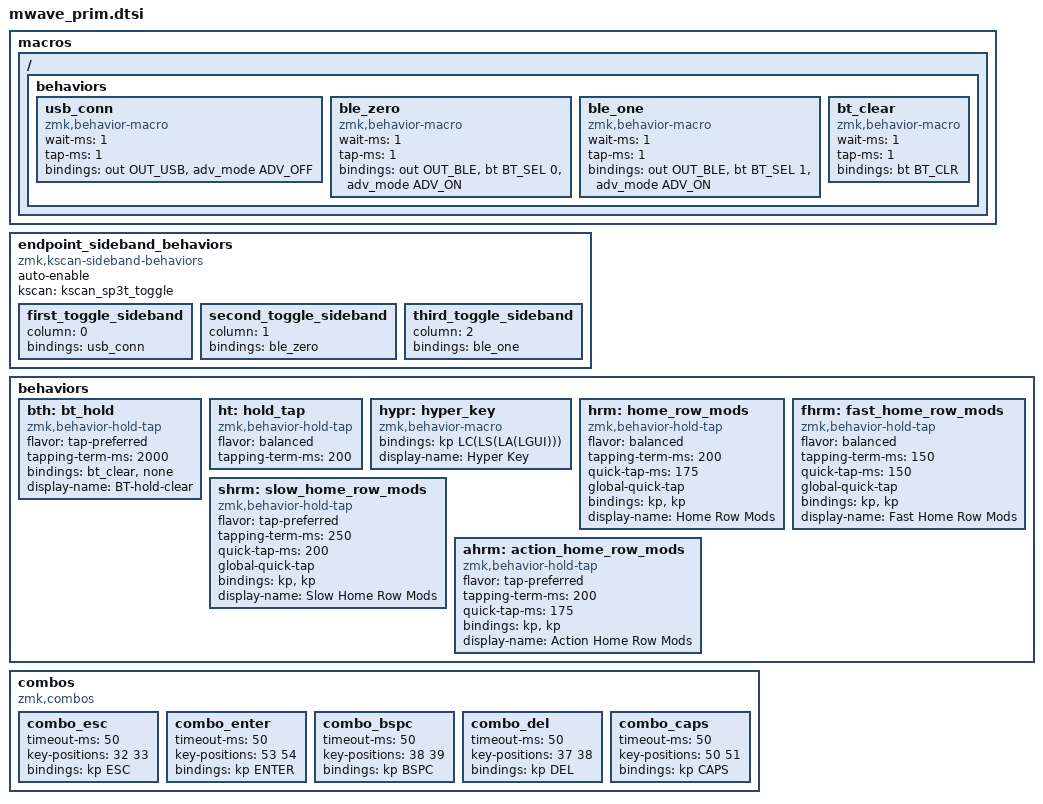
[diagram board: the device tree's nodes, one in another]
macros {
    ZMK_MACRO(usb_conn,
        wait-ms = <1>;
        tap-ms = <1>;
        bindings = <&out OUT_USB &adv_mode ADV_OFF>;
    )
    ZMK_MACRO(ble_zero,
        wait-ms = <1>;
        tap-ms = <1>;
        bindings = <&out OUT_BLE &bt BT_SEL 0 &adv_mode ADV_ON>;
    )
    ZMK_MACRO(ble_one,
        wait-ms = <1>;
        tap-ms = <1>;
        bindings = <&out OUT_BLE &bt BT_SEL 1 &adv_mode ADV_ON>;
    )
    ZMK_MACRO(bt_clear,
        wait-ms = <1>;
        tap-ms = <1>;
        bindings = <&bt BT_CLR>;
    )
    
    #include "version.dtsi"
};

endpoint_sideband_behaviors {
    auto-enable;
    compatible = "zmk,kscan-sideband-behaviors";
    kscan = <&kscan_sp3t_toggle>;

    first_toggle_sideband: first_toggle_sideband {
        column = <0>;
        bindings = <&usb_conn>;
    };

    second_toggle_sideband: second_toggle_sideband {
        column = <1>;
        bindings = <&ble_zero>;
    };

    third_toggle_sideband: third_toggle_sideband {
        column = <2>;
        bindings = <&ble_one>;
    };
};

behaviors {
    bth: bt_hold {
        compatible = "zmk,behavior-hold-tap";
        #binding-cells = <2>;
        flavor = "tap-preferred";
        tapping-term-ms = <2000>;
        bindings = <&bt_clear>, <&none>;
        display-name = "BT-hold-clear";
    };

    ht: hold_tap {
    compatible = "zmk,behavior-hold-tap";
    #binding-cells = <2>;
    flavor = "balanced";            // Balanced flavor for stability
    tapping-term-ms = <200>;        // Adjust tapping term for your typing speed
    };
    
    
    // Add just this one simple behavior definition
    hypr: hyper_key {
        compatible = "zmk,behavior-macro";
        #binding-cells = <0>;
        bindings = <&kp LC(LS(LA(LGUI)))>;
        display-name = "Hyper Key";
    };

    // Home row mods - start with just this definition
    hrm: home_row_mods {
        compatible = "zmk,behavior-hold-tap";
        #binding-cells = <2>;
        flavor = "balanced";
        tapping-term-ms = <200>;
        quick-tap-ms = <175>;
        global-quick-tap;
        bindings = <&kp>, <&kp>;
        display-name = "Home Row Mods";
    };

    // Fast home row mods (for frequently accessed modifiers)
    fhrm: fast_home_row_mods {
        compatible = "zmk,behavior-hold-tap";
        #binding-cells = <2>;
        flavor = "balanced";
        tapping-term-ms = <150>;  // Shorter tapping term for faster activation
        quick-tap-ms = <150>;
        global-quick-tap;
        bindings = <&kp>, <&kp>;
        display-name = "Fast Home Row Mods";
    };

    // Slow home row mods (for modifiers you don't want to trigger accidentally)
    shrm: slow_home_row_mods {
        compatible = "zmk,behavior-hold-tap";
        #binding-cells = <2>;
        flavor = "tap-preferred";  // More biased toward tapping
        tapping-term-ms = <250>;   // Longer tapping term for more deliberate holds
        quick-tap-ms = <200>;
        global-quick-tap;
        bindings = <&kp>, <&kp>;
        display-name = "Slow Home Row Mods";
    };

    // Action home row mods (for non-modifier actions like Tab and Enter)
    ahrm: action_home_row_mods {
        compatible = "zmk,behavior-hold-tap";
        #binding-cells = <2>;
        flavor = "tap-preferred";  // Better for action keys
        tapping-term-ms = <200>;
        quick-tap-ms = <175>;
        bindings = <&kp>, <&kp>;
        display-name = "Action Home Row Mods";
    };

}; 




// Key Positions Reference mwave33 
//---------------------------------------------------------------------------------
//Pos	Key	    Pos	Key	    Pos	Key	    Pos	Key	    Pos	Key	    Pos	Key	    Pos	Key
//---------------------------------------------------------------------------------
//	0	ESC	    1	F1	    2	F2	    3	F3	    4	F4	    5	F5	    6	F6
//	7	F7	    8	F8	    9	F9	    10	F10	    11	F11	    12	F12	    13	HOME
//	14	END	    15	INSERT	16	to 1	17	GRAVE	18	1	    19	2	    20	3
//	21	4	    22	5	    23	6	    24	7	    25	8	    26	9	    27	0
//	28	MINUS	29	EQUAL	30	BSPC	31	TAB	    32	Q	    33	W	    34	E
//	35	R	    36	T	    37	Y	    38	U	    39	I	    40	O	    41	P
//	42	LBKT	43	RBKT	44	BSLH	45	DEL	    46	CLCK	47	A	    48	S
//	49	D	    50	F	    51	G	    52	H	    53	J	    54	K	    55	L
//	56	SEMI	57	SQT	    58	RET	    59	PG_UP	60	LSHFT	61	Z	    62	X
//	63	C	    64	V	    65	B	    66	N	    67	M	    68	COMMA	69	DOT
//	70	FSLH	71	RSHFT	72	UP	    73	PG_DN	74	LCTRL	75	LGUI	76	LALT
//	77	SPACE	78	SPACE	79	RALT	80	K_CMENU	81	RCTRL	82	LEFT	83	DOWN
//	84	RIGHT												
//----------------------------------------------------------------------------------



combos {
    compatible = "zmk,combos";
    
    // Your existing combos
    combo_esc {
        timeout-ms = <50>;
        key-positions = <32 33>;  // Q and W keys
        bindings = <&kp ESC>;
    };
    
    combo_enter {
        timeout-ms = <50>;
        key-positions = <53 54>;  // J and K keys
        bindings = <&kp ENTER>;
    };
    
    
    // Backspace combo (U+I)
    combo_bspc {
        timeout-ms = <50>;
        key-positions = <38 39>;  // U and I keys
        bindings = <&kp BSPC>;
    };
    
  
    
    // Delete combo (Y+U)
    combo_del {
        timeout-ms = <50>;
        key-positions = <37 38>;  // Y and U keys
        bindings = <&kp DEL>;
    };
    
    // Caps Lock combo (F+G)
    combo_caps {
        timeout-ms = <50>;
        key-positions = <50 51>;  // F and G keys
        bindings = <&kp CAPS>;
    };
    

};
